# MM32SPIN05xq register map
File version: 1.01
CPU: CM0 r0p0, little endian, no MPU, no FPU, 2 interrupt priority bits
Registers are 32-bit, read-write, reset 0x0 unless marked. A register's access mark holds for its fields unless they carry their own. Offsets are from the block's base; [hi:lo] are bit positions; {n}, {i} and the like mark numbered series.

## EXTI — External interrupt/event controller
Base 0x40010000
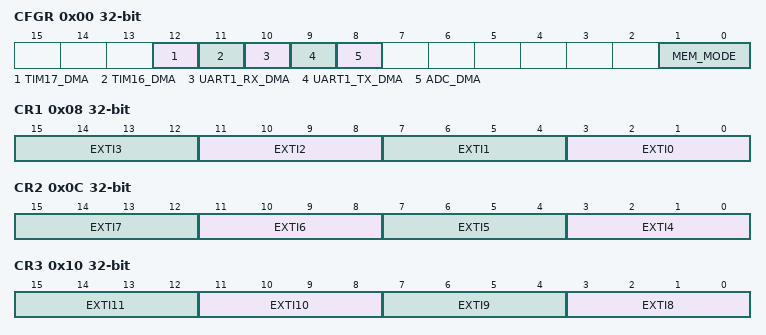
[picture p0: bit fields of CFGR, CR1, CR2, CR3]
0x00 CFGR — Configuration register
  [12] TIM17_DMA — TIM17_DMA_RMP
  [11] TIM16_DMA — TIM16_DMA_RMP
  [10] UART1_RX_DMA — UART1_RX_DMA_RMP
  [9] UART1_TX_DMA — UART1_TX_DMA_RMP
  [8] ADC_DMA — ADC_DMA_RMP
  [1:0] MEM_MODE
0x08 CR1 — External interrupt configuration register 1
  [4n+3:4n] EXTI{n} (n=0..3) — EXTI{n} configuration
0x0C CR2 — External interrupt configuration register 2
  [4n-13:4n-16] EXTI{n} (n=4..7) — EXTI{n} configuration
0x10 CR3 — External interrupt configuration register 3
  [4n-29:4n-32] EXTI{n} (n=8..11) — EXTI{n} configuration
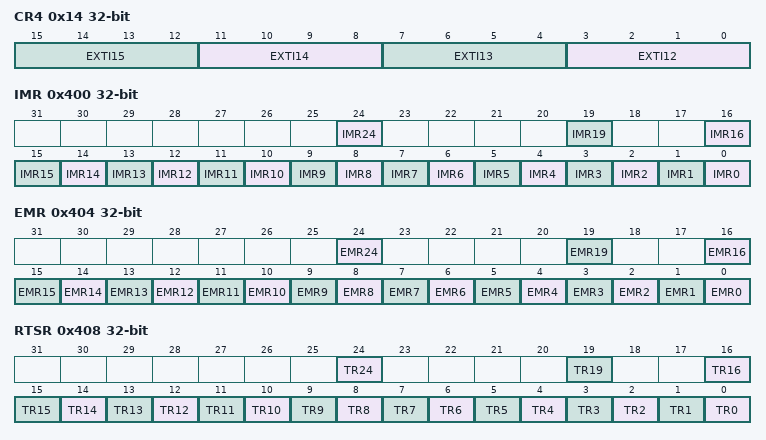
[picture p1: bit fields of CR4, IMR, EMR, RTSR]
0x14 CR4 — External interrupt configuration register 4
  [4n-45:4n-48] EXTI{n} (n=12..15) — EXTI{n} configuration
0x400 IMR — Interrupt mask register
  [24] IMR24 — Interrupt Mask on line 24
  [19] IMR19 — Interrupt Mask on line 19
  [n] IMR{n} (n=0..16) — Interrupt Mask on line {n}
0x404 EMR — Event mask register
  [24] EMR24 — Event Mask on line 24
  [19] EMR19 — Event Mask on line 19
  [n] EMR{n} (n=0..16) — Event Mask on line {n}
0x408 RTSR — Rising trigger selection register
  [24] TR24 — Rising trigger event configuration bit of line 24
  [19] TR19 — Rising trigger event configuration bit of line 19
  [n] TR{n} (n=0..16) — Rising trigger event configuration bit of line {n}
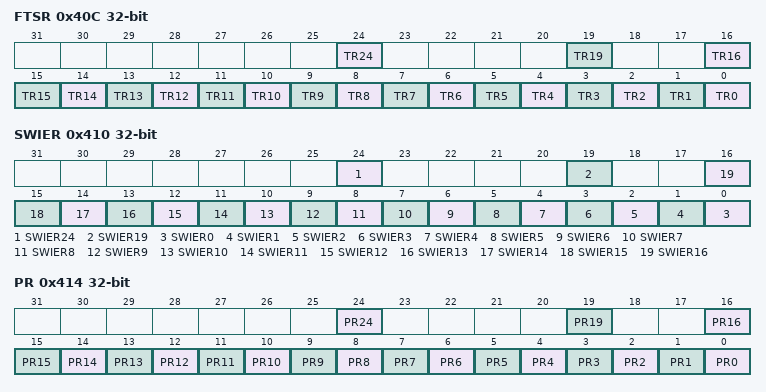
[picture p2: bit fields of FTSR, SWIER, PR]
0x40C FTSR — Falling trigger selection register
  [24] TR24 — Falling trigger event configuration bit of line 24
  [19] TR19 — Falling trigger event configuration bit of line 19
  [n] TR{n} (n=0..16) — Falling trigger event configuration bit of line {n}
0x410 SWIER — Software interrupt event register
  [24] SWIER24 — Software interrupt on line 24
  [19] SWIER19 — Software interrupt on line 19
  [n] SWIER{n} (n=0..16) — Software interrupt on line {n}
0x414 PR — Pending register
  [24] PR24 — Pending bit
  [19] PR19 — Pending bit
  [n] PR{n} (n=0..16) — Pending bit

## FLASH
Base 0x40022000
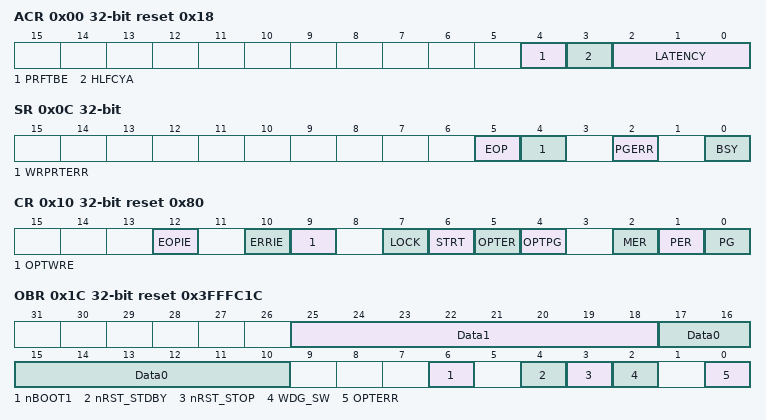
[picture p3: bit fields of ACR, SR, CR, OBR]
0x00 ACR reset 0x18 — Flash access control register
  [4] PRFTBE — Prefetch buffer enable
  [3] HLFCYA — Flash half cycle access enable
  [2:0] LATENCY
0x04 KEYR wo — Flash key
  [31:0] FKEYR
0x08 OPTKEYR wo — Option byte key
0x0C SR — Flash status register
  [5] EOP — End of operation
  [4] WRPRTERR — Write protection error
  [2] PGERR — Programming error
  [0] BSY — Busy
0x10 CR reset 0x80 — Flash control register
  [12] EOPIE — End of operation interrupt enable
  [10] ERRIE — Error interrupt enable
  [9] OPTWRE — Option byte write enable
  [7] LOCK
  [6] STRT — Start
  [5] OPTER — Option byte erase
  [4] OPTPG — Option byte programming
  [2] MER — Mass erase
  [1] PER — Page erase
  [0] PG — Programming
0x14 AR wo — Flash address register
  [31:0] FAR — Flash Address
0x1C OBR ro reset 0x3FFFC1C — Option byte register
  [25:18] Data1
  [17:10] Data0
  [6] nBOOT1
  [4] nRST_STDBY
  [3] nRST_STOP
  [2] WDG_SW
  [0] OPTERR — Option byte error
0x20 WRPR ro reset 0xFFFFFFFF — Write protect register
  [31:0] WRP — Write protect

## GPIOA — General purpose I/O
Base 0x48000000
Same registers: GPIOB 0x48000400, GPIOC 0x48000800, GPIOD 0x48000C00
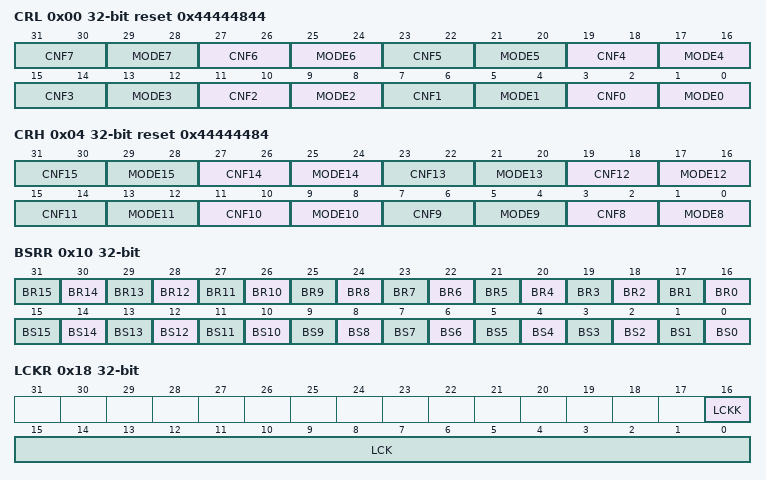
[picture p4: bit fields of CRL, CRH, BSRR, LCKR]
0x00 CRL reset 0x44444844 — configuration low register
  [4n+3:4n+2] CNF{n} (n=0..7) — Port {n} configuration bits
  [4n+1:4n] MODE{n} (n=0..7) — Port {n} mode bits
0x04 CRH reset 0x44444484 — configuration high register
  [4n-29:4n-30] CNF{n} (n=8..15) — Port {n} configuration bits
  [4n-31:4n-32] MODE{n} (n=8..15) — Port {n} mode bits
0x08 IDR ro — input data register
  [15:0] IDR — Port input data
0x0C ODR reset 0x204 — output data register
  [15:0] ODR — Port output data
0x10 BSRR wo — bit set/reset register
  [n+16] BR{n} (n=0..15) — Port x Reset bit {n}
  [n] BS{n} (n=0..15) — Port x Set bit {n}
0x14 BRR wo — bit reset register
  [15:0] BR — Port x Reset bit y
0x18 LCKR — Port configuration lock register
  [16] LCKK — Lock key
  [15:0] LCK — Port x Lock bit y
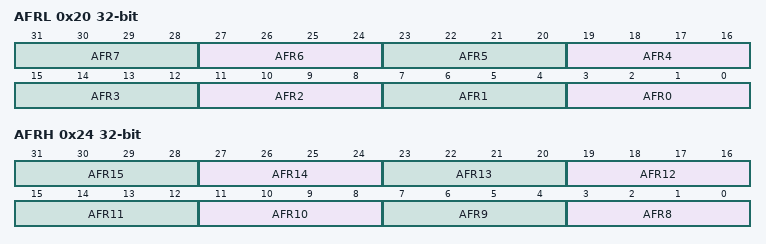
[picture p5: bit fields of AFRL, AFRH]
0x20 AFRL — Port Multiplexing Function Low Register
  [4n+3:4n] AFR{n} (n=0..7) — Multiplexing function selection for bit {n} of portx
0x24 AFRH — Port Multiplexing Function High Register
  [4n-29:4n-32] AFR{n} (n=8..15) — Multiplexing function selection for bit {n} of portx
